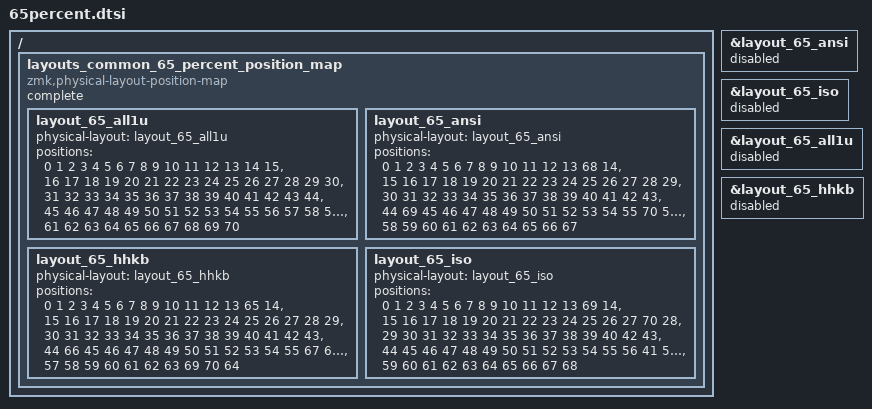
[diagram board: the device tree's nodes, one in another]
#include <layouts/common/65percent/ansi.dtsi>
#include <layouts/common/65percent/iso.dtsi>
#include <layouts/common/65percent/all1u.dtsi>
#include <layouts/common/65percent/hhkb.dtsi>

&layout_65_ansi {
    status = "disabled";
};

&layout_65_iso {
    status = "disabled";
};

&layout_65_all1u {
    status = "disabled";
};

&layout_65_hhkb {
    status = "disabled";
};

/ {
    layouts_common_65_percent_position_map: layouts_common_65_percent_position_map {
        compatible = "zmk,physical-layout-position-map";

        complete;

        layout_65_all1u {
            physical-layout = <&layout_65_all1u>;
            positions
                = < 0  1  2  3  4  5  6  7  8  9 10 11 12 13 14 15>
                , <16 17 18 19 20 21 22 23 24 25 26 27 28 29 30>
                , <31 32 33 34 35 36 37 38 39 40 41 42 43 44>
                , <45 46 47 48 49 50 51 52 53 54 55 56 57 58 59 60>
                , <61 62 63 64 65 66 67 68 69 70>
                ;
        };

        layout_65_ansi {
            physical-layout = <&layout_65_ansi>;
            positions
                = < 0  1  2  3  4  5  6  7  8  9 10 11 12 13 68 14>
                , <15 16 17 18 19 20 21 22 23 24 25 26 27 28 29>
                , <30 31 32 33 34 35 36 37 38 39 40 41 42 43>
                , <44 69 45 46 47 48 49 50 51 52 53 54 55 70 56 57>
                , <58 59 60 61 62 63 64 65 66 67>
                ;
        };

        layout_65_hhkb {
            physical-layout = <&layout_65_hhkb>;
            positions
                = < 0  1  2  3  4  5  6  7  8  9 10 11 12 13 65 14>
                , <15 16 17 18 19 20 21 22 23 24 25 26 27 28 29>
                , <30 31 32 33 34 35 36 37 38 39 40 41 42 43>
                , <44 66 45 46 47 48 49 50 51 52 53 54 55 67 68 56>
                , <57 58 59 60 61 62 63 69 70 64>
                ;
        };

        layout_65_iso {
            physical-layout = <&layout_65_iso>;
            positions
                = < 0  1  2  3  4  5  6  7  8  9 10 11 12 13 69 14>
                , <15 16 17 18 19 20 21 22 23 24 25 26 27 70 28>
                , <29 30 31 32 33 34 35 36 37 38 39 40 42 43>
                , <44 45 46 47 48 49 50 51 52 53 54 55 56 41 57 58>
                , <59 60 61 62 63 64 65 66 67 68>
                ;
        };
    };
};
